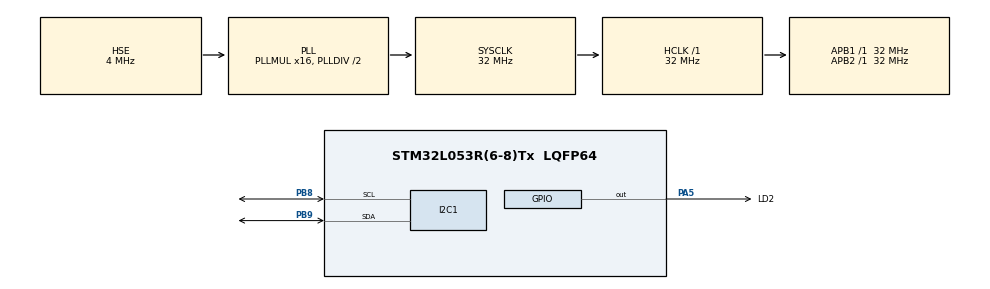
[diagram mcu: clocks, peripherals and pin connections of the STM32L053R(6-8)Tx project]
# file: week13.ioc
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I2C1.Timing=0x00707CBB
Mcu.Family=STM32L0
Mcu.Name=STM32L053R(6-8)Tx
Mcu.Package=LQFP64
PA13.Mode=Serial_Wire
PA13.Signal=SYS_SWDIO
PA14.Mode=Serial_Wire
PA14.Signal=SYS_SWCLK
PA5.GPIO_Label=LD2
PA5.Signal=GPIO_Output
PB8.Mode=I2C
PB8.Signal=I2C1_SCL
PB9.Mode=I2C
PB9.Signal=I2C1_SDA
PH0-OSC_IN.Mode=HSE-External-Oscillator
PH0-OSC_IN.Signal=RCC_OSC_IN
PH1-OSC_OUT.Mode=HSE-External-Oscillator
PH1-OSC_OUT.Signal=RCC_OSC_OUT
ProjectManager.HeapSize=0x200
ProjectManager.StackSize=0x400
ProjectManager.TargetToolchain=MDK-ARM V5.27
RCC.AHBFreq_Value=32000000
RCC.APB1Freq_Value=32000000
RCC.APB1TimFreq_Value=32000000
RCC.APB2Freq_Value=32000000
RCC.APB2TimFreq_Value=32000000
RCC.HCLKFreq_Value=32000000
RCC.HSE_VALUE=4000000
RCC.HSI16_VALUE=16000000
RCC.HSI48_VALUE=48000000
RCC.HSI_VALUE=16000000
RCC.LSE_VALUE=32768
RCC.MSI_VALUE=2097000
RCC.PLLMUL=RCC_PLLMUL_16
RCC.PLLSourceVirtual=RCC_PLLSOURCE_HSE
RCC.SYSCLKFreq_VALUE=32000000
RCC.SYSCLKSource=RCC_SYSCLKSOURCE_PLLCLK
RCC.VCOOutputFreq_Value=64000000
board=custom

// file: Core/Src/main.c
/* USER CODE BEGIN Header */
/**
  ******************************************************************************
  * @file           : main.c
  * @brief          : Main program body
  ******************************************************************************
  * @attention
  *
  * <h2><center>&copy; Copyright (c) 2021 STMicroelectronics.
  * All rights reserved.</center></h2>
  *
  * This software component is licensed by ST under BSD 3-Clause license,
  * the "License"; You may not use this file except in compliance with the
  * License. You may obtain a copy of the License at:
  *                        opensource.org/licenses/BSD-3-Clause
  *
  ******************************************************************************
  */
/* USER CODE END Header */
#include "main.h"
#include "i2c.h"
#include "gpio.h"

/* USER CODE BEGIN Includes */
#include <stdio.h>
#include <string.h>
/* USER CODE END Includes */

void SystemClock_Config(void);

/* USER CODE BEGIN 0 */
extern void lcd_set_cursor(uint8_t, uint8_t);
extern void lcd_print(char*, uint8_t);
extern void lcd_clear(void);
extern void lcd_init(void);
/* USER CODE END 0 */

int main(void)
{

  /* MCU Configuration--------------------------------------------------------*/

  /* Reset of all peripherals, Initializes the Flash interface and the Systick. */
  HAL_Init();

  /* Configure the system clock */
  SystemClock_Config();

  /* Initialize all configured peripherals */
  MX_GPIO_Init();
  MX_I2C1_Init();
  /* USER CODE BEGIN 2 */
  lcd_init();
  /* USER CODE END 2 */

  /* Infinite loop */
  /* USER CODE BEGIN WHILE */
  while (1)
  {
    char str[16] = "Hello World";
    lcd_set_cursor(1, 0);
    lcd_print(str, strlen(str));

    sprintf(str, "%d", HAL_GetTick());
    lcd_set_cursor(3, 1);
    lcd_print(str, strlen(str));

    HAL_Delay(1000);
    lcd_clear();
    /* USER CODE END WHILE */

  }
}

void SystemClock_Config(void)
{
  RCC_OscInitTypeDef RCC_OscInitStruct = {0};
  RCC_ClkInitTypeDef RCC_ClkInitStruct = {0};
  RCC_PeriphCLKInitTypeDef PeriphClkInit = {0};

  /** Configure the main internal regulator output voltage
  */
  __HAL_PWR_VOLTAGESCALING_CONFIG(PWR_REGULATOR_VOLTAGE_SCALE1);
  /** Initializes the RCC Oscillators according to the specified parameters
  * in the RCC_OscInitTypeDef structure.
  */
  RCC_OscInitStruct.OscillatorType = RCC_OSCILLATORTYPE_HSE;
  RCC_OscInitStruct.HSEState = RCC_HSE_ON;
  RCC_OscInitStruct.PLL.PLLState = RCC_PLL_ON;
  RCC_OscInitStruct.PLL.PLLSource = RCC_PLLSOURCE_HSE;
  RCC_OscInitStruct.PLL.PLLMUL = RCC_PLLMUL_16;
  RCC_OscInitStruct.PLL.PLLDIV = RCC_PLLDIV_2;
  if (HAL_RCC_OscConfig(&RCC_OscInitStruct) != HAL_OK)
  {
    Error_Handler();
  }
  /** Initializes the CPU, AHB and APB buses clocks
  */
  RCC_ClkInitStruct.ClockType = RCC_CLOCKTYPE_HCLK|RCC_CLOCKTYPE_SYSCLK
                              |RCC_CLOCKTYPE_PCLK1|RCC_CLOCKTYPE_PCLK2;
  RCC_ClkInitStruct.SYSCLKSource = RCC_SYSCLKSOURCE_PLLCLK;
  RCC_ClkInitStruct.AHBCLKDivider = RCC_SYSCLK_DIV1;
  RCC_ClkInitStruct.APB1CLKDivider = RCC_HCLK_DIV1;
  RCC_ClkInitStruct.APB2CLKDivider = RCC_HCLK_DIV1;

  if (HAL_RCC_ClockConfig(&RCC_ClkInitStruct, FLASH_LATENCY_1) != HAL_OK)
  {
    Error_Handler();
  }
  PeriphClkInit.PeriphClockSelection = RCC_PERIPHCLK_I2C1;
  PeriphClkInit.I2c1ClockSelection = RCC_I2C1CLKSOURCE_PCLK1;
  if (HAL_RCCEx_PeriphCLKConfig(&PeriphClkInit) != HAL_OK)
  {
    Error_Handler();
  }
}

void Error_Handler(void)
{
  __disable_irq();
  while (1)
  {
  }
}

/************************ (C) COPYRIGHT STMicroelectronics *****END OF FILE****/
